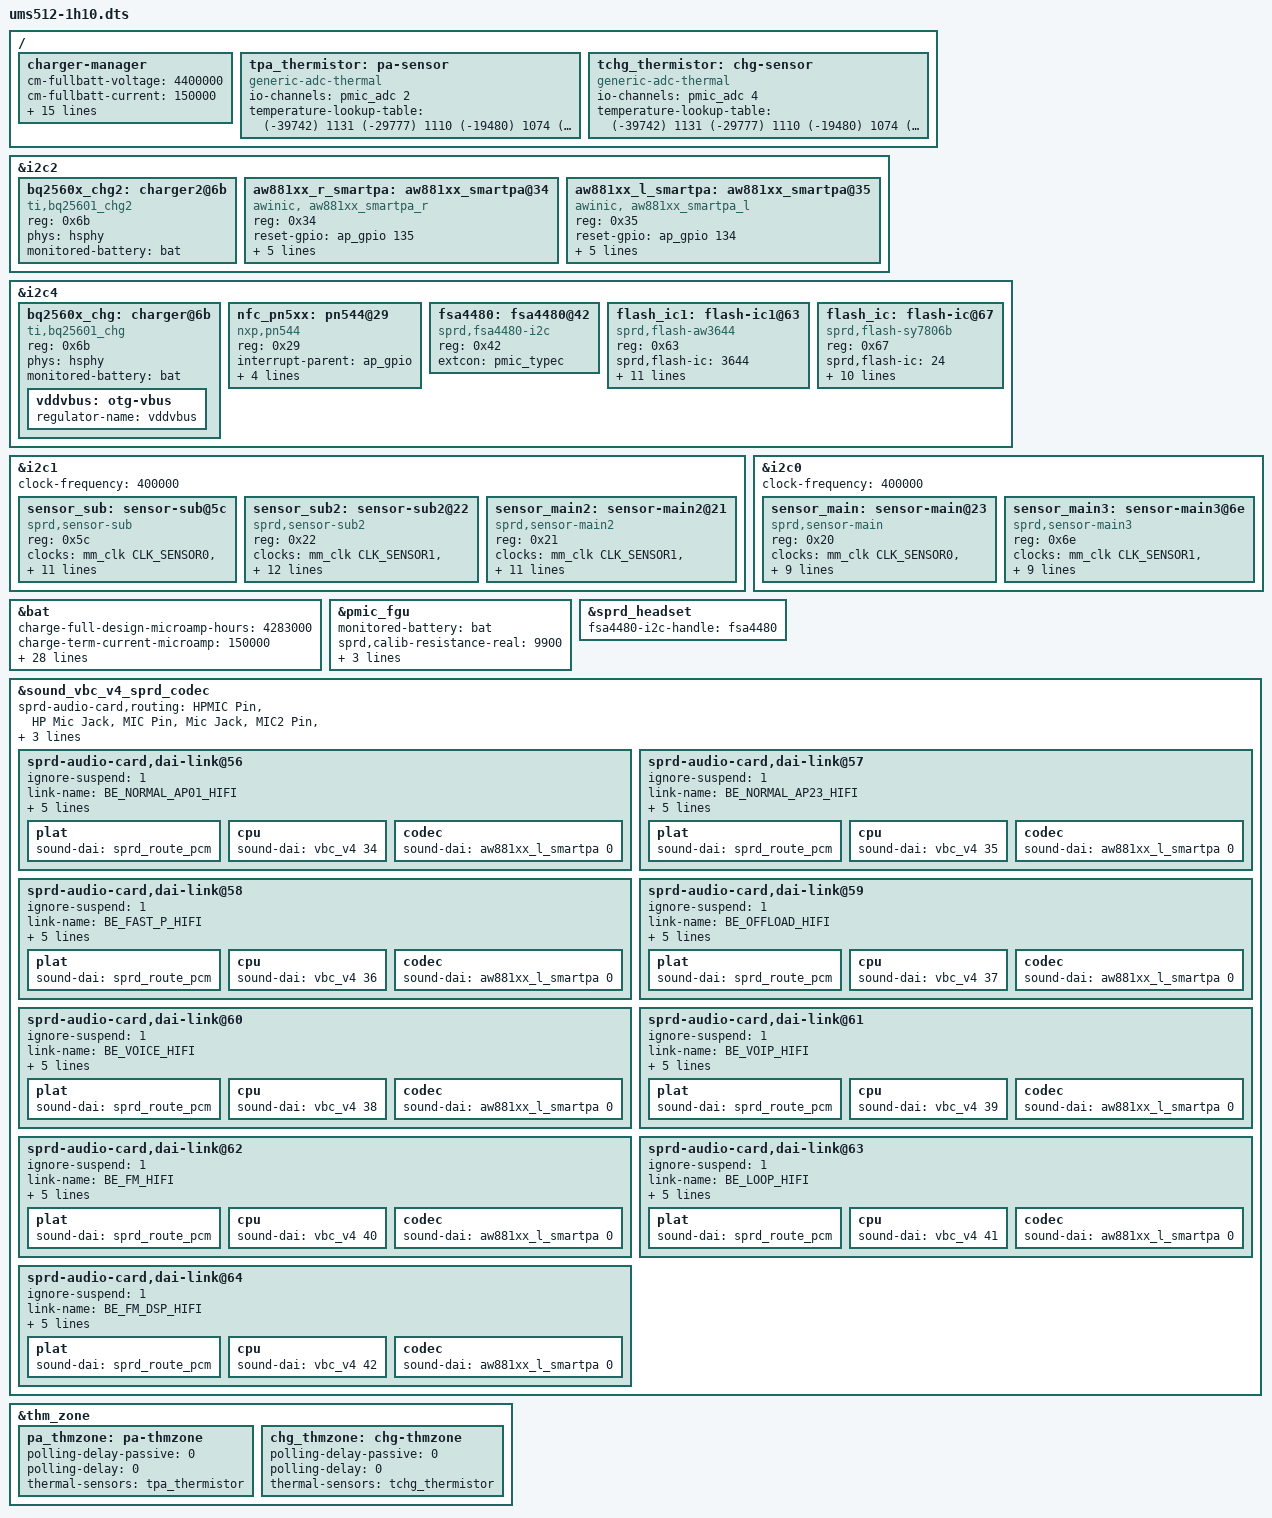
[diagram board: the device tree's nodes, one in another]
/*****************************************
Do not modify dts file, please modify according dtsi file
******************************************/

#include "../ums512-1h10.dts"
#include "sprd_base_diff.dtsi"

&i2c2 {
	bq2560x_chg2: charger2@6b {
		compatible = "ti,bq25601_chg2";
		reg = <0x6b>;
		phys = <&hsphy>;
		monitored-battery = <&bat>;
	};
};

&i2c4 {
	/delete-node/ charger@6a;
};

&i2c4 {
	bq2560x_chg: charger@6b {
		compatible = "ti,bq25601_chg";
		reg = <0x6b>;
		phys = <&hsphy>;
		monitored-battery = <&bat>;
		vddvbus:otg-vbus {
			regulator-name = "vddvbus";
		};
	};
};

&i2c4 {
	//status = "okay";
	//clock-frequency = <400000>;
		nfc_pn5xx: pn544@29 {
		compatible = "nxp,pn544";
		reg = <0x29>;
		interrupt-parent = <&ap_gpio>;
		interrupts = <53 0>;
		nxp,pn544-irq = <&ap_gpio 53 0>;
		nxp,pn544-ven = <&ap_gpio 137 0>;
		nxp,pn544-fw-dwnld = <&ap_gpio 88 0>;
		interrupt-names = "nfc_int";
	};
};

&i2c1 {
	/delete-node/ sensor-main3@6c;
};

&i2c0 {
	/delete-node/ sensor-sub@5a;
};

&i2c0 {
	/delete-node/ sensor-main@20;
};

&i2c1 {
	/delete-node/ sensor-sub2@6e;
};

&i2c1 {
	/delete-node/ sensor-main2@20;
};

&i2c1 {
	status = "okay";
	clock-frequency = <400000>;

	// front camera: 32M
	sensor_sub: sensor-sub@5c {
		compatible = "sprd,sensor-sub";
		reg = <0x5c>;
		clock-names = "clk_src","sensor_eb",
			"clk_96m","clk_76m8",
			"clk_48m","clk_26m";
		clocks = <&mm_clk CLK_SENSOR0>,<&mm_gate CLK_MM_SENSOR0_EB>,
				<&pll2 CLK_TWPLL_96M>,<&pll2 CLK_TWPLL_76M8>,
				<&pll2 CLK_TWPLL_48M>,<&ext_26m>;

		vddio-supply = <&vddcamio>;
		vddcamd-supply = <&vddcamd0>;
		reset-gpios = <&ap_gpio 41 0>;
		//power-down-gpios = <&ap_gpio 46 0>;
		mipi-switch-en-gpios = <&ap_gpio 55 0>;
		mipi-switch-mode-gpios = <&ap_gpio 8 0>;
		avdd-gpios=<&ap_gpio 132 0>;
		sprd,phyid = <1>;
		csi = <&csi0>;
	};

	//UWIDE: 8M
	sensor_sub2: sensor-sub2@22 {
		compatible = "sprd,sensor-sub2";
		reg = <0x22>;
		clock-names = "clk_src","sensor_eb",
			"clk_96m","clk_76m8",
			"clk_48m","clk_26m";
		clocks = <&mm_clk CLK_SENSOR1>,<&mm_gate CLK_MM_SENSOR1_EB>,
				<&pll2 CLK_TWPLL_96M>,<&pll2 CLK_TWPLL_76M8>,
				<&pll2 CLK_TWPLL_48M>,<&ext_26m>;
		vddio-supply = <&vddcamio>;
		vddcamd-supply = <&vddcamd1>;
		//vddcama-supply = <&vddcama>;
		avdd-gpios=<&ap_gpio 139 0>;
		reset-gpios = <&ap_gpio 45 0>;
		power-down-gpios = <&ap_gpio 47 0>;
		mipi-switch-en-gpios = <&ap_gpio 55 0>;
		mipi-switch-mode-gpios = <&ap_gpio 8 0>;
		sprd,phyid = <3>;
		csi = <&csi1>;
	};

	//DEPTH: 2M
	sensor_main2: sensor-main2@21 {
		compatible = "sprd,sensor-main2";
		reg = <0x21>;
		clock-names = "clk_src","sensor_eb",
			"clk_96m","clk_76m8",
			"clk_48m","clk_26m";
		clocks = <&mm_clk CLK_SENSOR1>,<&mm_gate CLK_MM_SENSOR1_EB>,
			<&pll2 CLK_TWPLL_96M>,<&pll2 CLK_TWPLL_76M8>,
			<&pll2 CLK_TWPLL_48M>,<&ext_26m>;
		vddio-supply = <&vddcamio>;
		vddcama-supply = <&vddcama1>;
		reset-gpios = <&ap_gpio 46 0>;
		dvdd-gpios=<&ap_gpio 60 0>;
		mipi-switch-en-gpios = <&ap_gpio 55 0>;
		mipi-switch-mode-gpios = <&ap_gpio 8 0>;
		sprd,phyid = <4>;
		csi = <&csi1>;
	};
};

&i2c0 {
	status = "okay";
	clock-frequency = <400000>;

	// main camera: 64M
	sensor_main: sensor-main@23 {
		compatible = "sprd,sensor-main";
		reg = <0x20>;
		clock-names = "clk_src","sensor_eb",
			"clk_96m","clk_76m8",
			"clk_48m","clk_26m";
		clocks = <&mm_clk CLK_SENSOR0>,<&mm_gate CLK_MM_SENSOR0_EB>,
				<&pll2 CLK_TWPLL_96M>,<&pll2 CLK_TWPLL_76M8>,
				<&pll2 CLK_TWPLL_48M>,<&ext_26m>;
		vddio-supply = <&vddcamio>;
		//vddcama-supply = <&vddcama>;
		//vddcamd-supply = <&vddcamd>;
		vddcammot-supply = <&vddcammot>;

		avdd-gpios=<&ap_gpio 123 0>;
		reset-gpios = <&ap_gpio 44 0>;
		sprd,phyid = <0>;
		csi = <&csi0>;
	};

	//macro: 2M
	sensor_main3: sensor-main3@6e {
		compatible = "sprd,sensor-main3";
		reg = <0x6e>;
		clock-names = "clk_src","sensor_eb",
			"clk_96m","clk_76m8",
			"clk_48m","clk_26m";
		clocks = <&mm_clk CLK_SENSOR1>,<&mm_gate CLK_MM_SENSOR1_EB>,
			<&pll2 CLK_TWPLL_96M>,<&pll2 CLK_TWPLL_76M8>,
			<&pll2 CLK_TWPLL_48M>,<&ext_26m>;
		vddio-supply = <&vddcamio>;
		dvdd-gpios=<&ap_gpio 60 0>;
		vddcama-supply = <&vddcama1>;
		reset-gpios = <&ap_gpio 40 0>;
		sprd,phyid = <2>;
		csi = <&csi1>;
	};
};


&bat {
		charge-full-design-microamp-hours = <4283000>;
		charge-term-current-microamp = <150000>;
		constant_charge_voltage_max_microvolt = <4450000>;
		constant_charge_current_max_microamp = <3400000>;
		factory-internal-resistance-micro-ohms = <165000>;
		voltage-min-design-microvolt = <3450000>;
		ocv-capacity-celsius = <25>;
		ocv-capacity-table-0 = <4430000 100>, <4375000 95>, <4320000 90>,
					<4261000 85>, <4201000 80>, <4141000 75>,
					<4086000 70>, <4033000 65>, <3986000 60>,
					<3927000 55>, <3880000 50>, <3851000 45>,
					<3827000 40>, <3810000 35>, <3794000 30>,
					<3775000 25>, <3753000 20>, <3728000 15>,
					<3698000 10>, <3687000 5>, <3400000 0>;
		/* NTC 100k, Vref 1850mV, R pull-up 110K, R pull-down 200k */
		voltage-temp-table = <1142302 750>, <1124233 800>, <1101233 850>,
					<1072536 900>, <1037442 950>, <995634 1000>,
					<946936 1050>, <891766 1100>, <830977 1150>,
					<765857 1200>, <698113 1250>, <629571 1300>,
					<562069 1350>, <497228 1400>, <436397 1450>,
					<380362 1500>, <329745 1550>, <284636 1600>,
					<244918 1650>, <210360 1700>, <180383 1750>;
		capacity-temp-table = <25 100>, <10 100>, <0 96>, <(-10) 88>, <(-20) 74>;
		resistance-temp-table = <25 100>, <10 149>, <0 718>, <(-10) 776>, <(-20) 857>;
		charge-sdp-current-microamp = <700000 500000>;
		charge-dcp-current-microamp = <3400000 3200000>;
		charge-cdp-current-microamp = <3400000 1500000>;
		charge-unknown-current-microamp = <700000 500000>;
};

&pmic_fgu {
	monitored-battery = <&bat>;
	sprd,calib-resistance-real = <9900>;
	sprd,calib-resistance-spec = <20000>;
	io-channels = <&pmic_adc 0>, <&pmic_adc 6>,<&pmic_adc 14>;
	io-channel-names = "bat-temp", "adc-batt-id", "charge-vol";
};

/ {
	charger-manager {
		cm-fullbatt-voltage = <4400000>;
		cm-fullbatt-current = <150000>;

		/* in deci centigrade */
		cm-battery-cold = <0>;
		cm-battery-hot = <550>;
		cm-battery-temp-diff = <30>;
		cm-tickle-time-out = <180>;
		cm-disable-charger-type-jeita;

		cm-jeita-temp-table = <1000 1030 0 4450000>,
				<1050 1080 2000000 4450000>,
				<1100 1130 2500000 4450000>,
				<1450 1420 3400000 4450000>,
				<1550 1520 1400000 4100000>;

		cm-chargers = "hook";
		cm-hardware-psy = "bq25601_charger";
		cm-hardware2-psy = "bq25601_charger2";
		monitored-battery = <&bat>;
		phys = <&hsphy>;
	};
};


&i2c2 {
	/delete-node/ ak4377@10;

	aw881xx_r_smartpa: aw881xx_smartpa@34 {
		#sound-dai-cells = <1>;
		compatible = "awinic, aw881xx_smartpa_r";
		reg = <0x34>;
		reset-gpio = <&ap_gpio 135 GPIO_ACTIVE_HIGH>;
		monitor-flag = <1>;
		monitor-timer-val = <30000>;
		sound-channel = "right";
		codecs-num = <2>;
		codec-id = <1>;
		status = "okay";
	};

	aw881xx_l_smartpa: aw881xx_smartpa@35 {
		compatible = "awinic, aw881xx_smartpa_l";
		reg = <0x35>;
		#sound-dai-cells = <1>;
		reset-gpio = <&ap_gpio 134 GPIO_ACTIVE_HIGH>;
		monitor-flag = <1>;
		monitor-timer-val = <30000>;
		sound-channel = "left";
		codecs-num = <2>;
		codec-id = <0>;
		status = "okay";
	};
};

&sprd_headset {
	fsa4480-i2c-handle = <&fsa4480>;
};

&i2c4 {
	/delete-node/ ucp1301@58;
	/delete-node/ flash-ic@63;

	fsa4480: fsa4480@42 {
		status = "okay";
		compatible = "sprd,fsa4480-i2c";
		reg = <0x42>;
		extcon = <&pmic_typec>;
	};

	flash_ic1: flash-ic1@63 {
		compatible = "sprd,flash-aw3644";
		reg = <0x63>;
		sprd,flash-ic = <3644>;
		sprd,torch = <1>;
		sprd,preflash = <1>;
		sprd,highlight = <1>;
		sprd,torch-level = <128>;
		sprd,preflash-level = <128>;
		sprd,highlight-level = <128>;
		sprd,lvfm-enable = <1>;
		flash-chip-en-gpios = <&ap_gpio 136 0>;
		flash-torch-en-gpios = <&ap_gpio 139 0>;
		flash-en-gpios = <&ap_gpio 137 0>;
		flash-sync-gpios = <&ap_gpio 138 0>;
	};

	flash_ic: flash-ic@67 {
		compatible = "sprd,flash-sy7806b";
		reg = <0x67>;
		sprd,flash-ic = <24>;
		sprd,torch = <1>;
		sprd,preflash = <1>;
		sprd,highlight = <1>;
		sprd,torch-level = <10>;
		sprd,preflash-level = <10>;
		sprd,highlight-level = <15>;
		sprd,lvfm-enable = <1>;
		flash-chip-en-gpios = <&ap_gpio 136 0>;
		flash-en-gpios = <&ap_gpio 76 0>;
		flash-sync-gpios = <&ap_gpio 141 0>;
	};
};

&sound_vbc_v4_sprd_codec {
	sprd-audio-card,routing =
		"HPMIC Pin", "HP Mic Jack",
		"MIC Pin", "Mic Jack",
		"MIC2 Pin", "Aux Mic Jack",
		"inter HP PA", "HP Pin",
		"inter Spk PA", "SPK Pin",
		"DMIC Pin", "DMic Jack",
		"DMIC1 Pin", "DMic1 Jack",
		"inter Ear PA", "EAR Pin";

	/delete-node/ sprd-audio-card,dai-link@53;

	/* 38: akm hifi normal ap01 */
	sprd-audio-card,dai-link@56 {
		ignore-suspend = <1>;
		link-name = "BE_NORMAL_AP01_HIFI";
		stream-name = "BE_ST_NORMAL_AP01_HIFI";
		no-pcm = <1>;
		dpcm-playback = <1>;
		be-id = <0>;
		dai-format = "i2s";
		plat {
			sound-dai = <&sprd_route_pcm>;
		};
		cpu {
			sound-dai = <&vbc_v4 34>;
		};
		codec {
			sound-dai = <&aw881xx_l_smartpa 0>;
		};
	};

	/* 39: akm hifi normal ap23 */
	sprd-audio-card,dai-link@57 {
		ignore-suspend = <1>;
		link-name = "BE_NORMAL_AP23_HIFI";
		stream-name = "BE_ST_NORMAL_AP23_HIFI";
		no-pcm = <1>;
		dpcm-playback = <1>;
		be-id = <0>;
		dai-format = "i2s";
		plat {
			sound-dai = <&sprd_route_pcm>;
		};
		cpu {
			sound-dai = <&vbc_v4 35>;
		};
		codec {
			sound-dai = <&aw881xx_l_smartpa 0>;
		};
	};

	/* 40: akm hifi fast playback */
	sprd-audio-card,dai-link@58 {
		ignore-suspend = <1>;
		link-name = "BE_FAST_P_HIFI";
		stream-name = "BE_ST_FAST_P_HIFI";
		no-pcm = <1>;
		dpcm-playback = <1>;
		be-id = <0>;
		dai-format = "i2s";
		plat {
			sound-dai = <&sprd_route_pcm>;
		};
		cpu {
			sound-dai = <&vbc_v4 36>;
		};
		codec {
			sound-dai = <&aw881xx_l_smartpa 0>;
		};
	};

	/* 41: akm hifi offload */
	sprd-audio-card,dai-link@59 {
		ignore-suspend = <1>;
		link-name = "BE_OFFLOAD_HIFI";
		stream-name = "BE_ST_OFFLOAD_HIFI";
		no-pcm = <1>;
		dpcm-playback = <1>;
		be-id = <0>;
		dai-format = "i2s";
		plat {
			sound-dai = <&sprd_route_pcm>;
		};
		cpu {
			sound-dai = <&vbc_v4 37>;
		};
		codec {
			sound-dai = <&aw881xx_l_smartpa 0>;
		};
	};

	/* 42: akm hifi voice */
	sprd-audio-card,dai-link@60 {
		ignore-suspend = <1>;
		link-name = "BE_VOICE_HIFI";
		stream-name = "BE_ST_VOICE_HIFI";
		no-pcm = <1>;
		dpcm-playback = <1>;
		be-id = <0>;
		dai-format = "i2s";
		plat {
			sound-dai = <&sprd_route_pcm>;
		};
		cpu {
			sound-dai = <&vbc_v4 38>;
		};
		codec {
			sound-dai = <&aw881xx_l_smartpa 0>;
		};
	};

	/* 43: akm hifi voip */
	sprd-audio-card,dai-link@61 {
		ignore-suspend = <1>;
		link-name = "BE_VOIP_HIFI";
		stream-name = "BE_DAI_ID_VOIP_HIFI";
		no-pcm = <1>;
		dpcm-playback = <1>;
		be-id = <0>;
		dai-format = "i2s";
		plat {
			sound-dai = <&sprd_route_pcm>;
		};
		cpu {
			sound-dai = <&vbc_v4 39>;
		};
		codec {
			sound-dai = <&aw881xx_l_smartpa 0>;
		};
	};

	/* 44: akm hifi fm */
	sprd-audio-card,dai-link@62 {
		ignore-suspend = <1>;
		link-name = "BE_FM_HIFI";
		stream-name = "BE_ST_FM_HIFI";
		no-pcm = <1>;
		dpcm-playback = <1>;
		be-id = <0>;
		dai-format = "i2s";
		plat {
			sound-dai = <&sprd_route_pcm>;
		};
		cpu {
			sound-dai = <&vbc_v4 40>;
		};
		codec {
			sound-dai = <&aw881xx_l_smartpa 0>;
		};
	};

	/* 45: akm hifi loopback */
	sprd-audio-card,dai-link@63 {
		ignore-suspend = <1>;
		link-name = "BE_LOOP_HIFI";
		stream-name = "BE_ST_LOOP_HIFI";
		no-pcm = <1>;
		dpcm-playback = <1>;
		be-id = <0>;
		dai-format = "i2s";
		plat {
			sound-dai = <&sprd_route_pcm>;
		};
		cpu {
			sound-dai = <&vbc_v4 41>;
		};
		codec {
			sound-dai = <&aw881xx_l_smartpa 0>;
		};
	};

	/* 46: akm hifi fm dsp */
	sprd-audio-card,dai-link@64 {
		ignore-suspend = <1>;
		link-name = "BE_FM_DSP_HIFI";
		stream-name = "BE_ST_FM_DSP_HIFI";
		no-pcm = <1>;
		dpcm-playback = <1>;
		be-id = <0>;
		dai-format = "i2s";
		plat {
			sound-dai = <&sprd_route_pcm>;
		};
		cpu {
			sound-dai = <&vbc_v4 42>;
		};
		codec {
			sound-dai = <&aw881xx_l_smartpa 0>;
		};
	};
};
/ {
	tpa_thermistor:pa-sensor {
		compatible = "generic-adc-thermal";
		#thermal-sensor-cells = <0>;
		io-channels = <&pmic_adc 2>;
		io-channel-names = "sensor-channel";
		temperature-lookup-table = <	(-39742) 1131
						(-29777) 1110
						(-19480) 1074
						(-4679) 983
						10110 838
						24805 654
						44922 413
						54903 316
						64895 238
						74884 178
						84883 133
						94883 100
						104880 75
						114889 57
						124872 43 >;
	};

	tchg_thermistor:chg-sensor {
		compatible = "generic-adc-thermal";
		#thermal-sensor-cells = <0>;
		io-channels = <&pmic_adc 4>;
		io-channel-names = "sensor-channel";
		temperature-lookup-table = <	(-39742) 1131
						(-29777) 1110
						(-19480) 1074
						(-4679) 983
						10110 838
						24805 654
						44922 413
						54903 316
						64895 238
						74884 178
						84883 133
						94883 100
						104880 75
						114889 57
						124872 43 >;
	};
};

&thm_zone {
	pa_thmzone: pa-thmzone {
		polling-delay-passive = <0>;
		polling-delay = <0>;
		thermal-sensors = <&tpa_thermistor>;
	};
};

&thm_zone {
	chg_thmzone: chg-thmzone {
		polling-delay-passive = <0>;
		polling-delay = <0>;
		thermal-sensors = <&tchg_thermistor>;
	};
};
